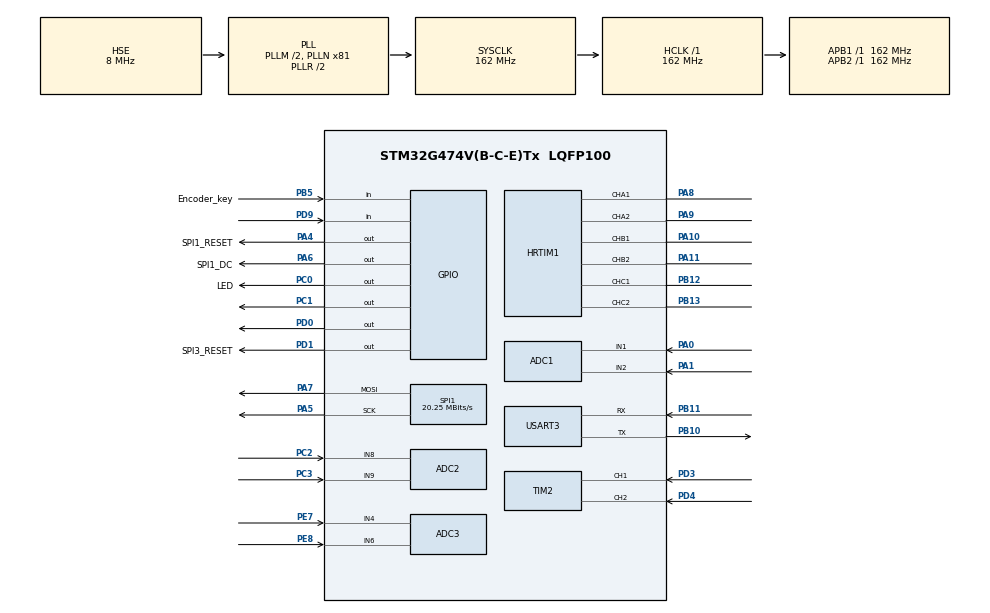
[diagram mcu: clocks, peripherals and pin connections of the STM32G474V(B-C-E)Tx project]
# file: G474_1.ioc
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ADC1.Channel-6\#ChannelRegularConversion=ADC_CHANNEL_1
ADC1.Channel-7\#ChannelRegularConversion=ADC_CHANNEL_2
ADC1.ClockPrescaler=ADC_CLOCK_ASYNC_DIV4
ADC1.ContinuousConvMode=DISABLE
ADC1.DMAAccessModeView=ENABLE
ADC1.DMAContinuousRequests=ENABLE
ADC1.DiscontinuousConvMode=DISABLE
ADC1.EnableAnalogWatchDog1=false
ADC1.EnableInjectedConversion=DISABLE
ADC1.EnableRegularConversion=ENABLE
ADC1.ExternalTrigConv=ADC_EXTERNALTRIG_HRTIM_TRG5
ADC1.ExternalTrigConvEdge=ADC_EXTERNALTRIGCONVEDGE_RISING
ADC1.Mode=ADC_DUALMODE_REGSIMULT
ADC1.NbrOfConversion=2
ADC1.NbrOfConversionFlag=1
ADC1.OffsetNumber-6\#ChannelRegularConversion=ADC_OFFSET_NONE
ADC1.OffsetNumber-7\#ChannelRegularConversion=ADC_OFFSET_NONE
ADC1.Overrun=ADC_OVR_DATA_OVERWRITTEN
ADC1.OversamplingMode=ENABLE
ADC1.OversamplingStopReset=ADC_REGOVERSAMPLING_CONTINUED_MODE
ADC1.Rank-6\#ChannelRegularConversion=1
ADC1.Rank-7\#ChannelRegularConversion=2
ADC1.Ratio=ADC_OVERSAMPLING_RATIO_4
ADC1.RightBitShift=ADC_RIGHTBITSHIFT_2
ADC1.SamplingTime-6\#ChannelRegularConversion=ADC_SAMPLETIME_12CYCLES_5
ADC1.SamplingTime-7\#ChannelRegularConversion=ADC_SAMPLETIME_12CYCLES_5
ADC1.TriggeredMode=ADC_TRIGGEREDMODE_SINGLE_TRIGGER
ADC1.master=1
ADC2.Channel-3\#ChannelRegularConversion=ADC_CHANNEL_8
ADC2.Channel-4\#ChannelRegularConversion=ADC_CHANNEL_9
ADC2.ClockPrescaler=ADC_CLOCK_ASYNC_DIV4
ADC2.DMAAccessModeView=ENABLE
ADC2.Mode=ADC_DUALMODE_REGSIMULT
ADC2.NbrOfConversion=2
ADC2.NbrOfConversionFlag=1
ADC2.OffsetNumber-3\#ChannelRegularConversion=ADC_OFFSET_NONE
ADC2.OffsetNumber-4\#ChannelRegularConversion=ADC_OFFSET_NONE
ADC2.Overrun=ADC_OVR_DATA_OVERWRITTEN
ADC2.OversamplingMode=ENABLE
ADC2.Rank-3\#ChannelRegularConversion=1
ADC2.Rank-4\#ChannelRegularConversion=2
ADC2.Ratio=ADC_OVERSAMPLING_RATIO_4
ADC2.RightBitShift=ADC_RIGHTBITSHIFT_2
ADC2.SamplingTime-3\#ChannelRegularConversion=ADC_SAMPLETIME_12CYCLES_5
ADC2.SamplingTime-4\#ChannelRegularConversion=ADC_SAMPLETIME_12CYCLES_5
ADC3.Channel-0\#ChannelRegularConversion=ADC_CHANNEL_4
ADC3.Channel-1\#ChannelRegularConversion=ADC_CHANNEL_6
ADC3.DMAContinuousRequests=ENABLE
ADC3.ExternalTrigConv=ADC_EXTERNALTRIG_HRTIM_TRG5
ADC3.Mode=ADC_MODE_INDEPENDENT
ADC3.NbrOfConversion=2
ADC3.NbrOfConversionFlag=1
ADC3.OffsetNumber-0\#ChannelRegularConversion=ADC_OFFSET_NONE
ADC3.OffsetNumber-1\#ChannelRegularConversion=ADC_OFFSET_NONE
ADC3.Overrun=ADC_OVR_DATA_OVERWRITTEN
ADC3.OversamplingMode=ENABLE
ADC3.Rank-0\#ChannelRegularConversion=1
ADC3.Rank-1\#ChannelRegularConversion=2
ADC3.Ratio=ADC_OVERSAMPLING_RATIO_4
ADC3.RightBitShift=ADC_RIGHTBITSHIFT_2
ADC3.SamplingTime-0\#ChannelRegularConversion=ADC_SAMPLETIME_12CYCLES_5
ADC3.SamplingTime-1\#ChannelRegularConversion=ADC_SAMPLETIME_12CYCLES_5
ADC3.master=1
Dma.ADC1.1.Direction=DMA_PERIPH_TO_MEMORY
Dma.ADC1.1.EventEnable=DISABLE
Dma.ADC1.1.Instance=DMA1_Channel1
Dma.ADC1.1.MemDataAlignment=DMA_MDATAALIGN_WORD
Dma.ADC1.1.MemInc=DMA_MINC_ENABLE
Dma.ADC1.1.Mode=DMA_CIRCULAR
Dma.ADC1.1.PeriphDataAlignment=DMA_PDATAALIGN_WORD
Dma.ADC1.1.PeriphInc=DMA_PINC_DISABLE
Dma.ADC1.1.Polarity=HAL_DMAMUX_REQ_GEN_RISING
Dma.ADC1.1.Priority=DMA_PRIORITY_MEDIUM
Dma.ADC1.1.RequestNumber=1
Dma.ADC1.1.SignalID=NONE
Dma.ADC1.1.SyncEnable=DISABLE
Dma.ADC1.1.SyncPolarity=HAL_DMAMUX_SYNC_NO_EVENT
Dma.ADC1.1.SyncRequestNumber=1
Dma.ADC1.1.SyncSignalID=NONE
Dma.ADC3.2.Direction=DMA_PERIPH_TO_MEMORY
Dma.ADC3.2.EventEnable=DISABLE
Dma.ADC3.2.Instance=DMA1_Channel2
Dma.ADC3.2.MemDataAlignment=DMA_MDATAALIGN_HALFWORD
Dma.ADC3.2.MemInc=DMA_MINC_ENABLE
Dma.ADC3.2.Mode=DMA_CIRCULAR
Dma.ADC3.2.PeriphDataAlignment=DMA_PDATAALIGN_HALFWORD
Dma.ADC3.2.PeriphInc=DMA_PINC_DISABLE
Dma.ADC3.2.Polarity=HAL_DMAMUX_REQ_GEN_RISING
Dma.ADC3.2.Priority=DMA_PRIORITY_MEDIUM
Dma.ADC3.2.RequestNumber=1
Dma.ADC3.2.SignalID=NONE
Dma.ADC3.2.SyncEnable=DISABLE
Dma.ADC3.2.SyncPolarity=HAL_DMAMUX_SYNC_NO_EVENT
Dma.ADC3.2.SyncRequestNumber=1
Dma.ADC3.2.SyncSignalID=NONE
Dma.Request0=SPI1_TX
Dma.Request1=ADC1
Dma.Request2=ADC3
Dma.Request3=USART3_TX
Dma.Request4=USART3_RX
Dma.SPI1_TX.0.Direction=DMA_MEMORY_TO_PERIPH
Dma.SPI1_TX.0.EventEnable=DISABLE
Dma.SPI1_TX.0.Instance=DMA2_Channel1
Dma.SPI1_TX.0.MemDataAlignment=DMA_MDATAALIGN_BYTE
Dma.SPI1_TX.0.MemInc=DMA_MINC_ENABLE
Dma.SPI1_TX.0.Mode=DMA_NORMAL
Dma.SPI1_TX.0.PeriphDataAlignment=DMA_PDATAALIGN_BYTE
Dma.SPI1_TX.0.PeriphInc=DMA_PINC_DISABLE
Dma.SPI1_TX.0.Polarity=HAL_DMAMUX_REQ_GEN_RISING
Dma.SPI1_TX.0.Priority=DMA_PRIORITY_HIGH
Dma.SPI1_TX.0.RequestNumber=1
Dma.SPI1_TX.0.SignalID=NONE
Dma.SPI1_TX.0.SyncEnable=DISABLE
Dma.SPI1_TX.0.SyncPolarity=HAL_DMAMUX_SYNC_NO_EVENT
Dma.SPI1_TX.0.SyncRequestNumber=1
Dma.SPI1_TX.0.SyncSignalID=NONE
Dma.USART3_RX.4.Direction=DMA_PERIPH_TO_MEMORY
Dma.USART3_RX.4.EventEnable=DISABLE
Dma.USART3_RX.4.Instance=DMA1_Channel4
Dma.USART3_RX.4.MemDataAlignment=DMA_MDATAALIGN_BYTE
Dma.USART3_RX.4.MemInc=DMA_MINC_ENABLE
Dma.USART3_RX.4.Mode=DMA_NORMAL
Dma.USART3_RX.4.PeriphDataAlignment=DMA_PDATAALIGN_BYTE
Dma.USART3_RX.4.PeriphInc=DMA_PINC_DISABLE
Dma.USART3_RX.4.Polarity=HAL_DMAMUX_REQ_GEN_RISING
Dma.USART3_RX.4.Priority=DMA_PRIORITY_MEDIUM
Dma.USART3_RX.4.RequestNumber=1
Dma.USART3_RX.4.SignalID=NONE
Dma.USART3_RX.4.SyncEnable=DISABLE
Dma.USART3_RX.4.SyncPolarity=HAL_DMAMUX_SYNC_NO_EVENT
Dma.USART3_RX.4.SyncRequestNumber=1
Dma.USART3_RX.4.SyncSignalID=NONE
Dma.USART3_TX.3.Direction=DMA_MEMORY_TO_PERIPH
Dma.USART3_TX.3.EventEnable=DISABLE
Dma.USART3_TX.3.Instance=DMA1_Channel3
Dma.USART3_TX.3.MemDataAlignment=DMA_MDATAALIGN_BYTE
Dma.USART3_TX.3.MemInc=DMA_MINC_ENABLE
Dma.USART3_TX.3.Mode=DMA_NORMAL
Dma.USART3_TX.3.PeriphDataAlignment=DMA_PDATAALIGN_BYTE
Dma.USART3_TX.3.PeriphInc=DMA_PINC_DISABLE
Dma.USART3_TX.3.Polarity=HAL_DMAMUX_REQ_GEN_RISING
Dma.USART3_TX.3.Priority=DMA_PRIORITY_MEDIUM
Dma.USART3_TX.3.RequestNumber=1
Dma.USART3_TX.3.SignalID=NONE
Dma.USART3_TX.3.SyncEnable=DISABLE
Dma.USART3_TX.3.SyncPolarity=HAL_DMAMUX_SYNC_NO_EVENT
Dma.USART3_TX.3.SyncRequestNumber=1
Dma.USART3_TX.3.SyncSignalID=NONE
FREERTOS.Tasks01=defaultTask,24,1024,StartDefaultTask,Default,NULL,Dynamic,NULL,NULL
FREERTOS.configCHECK_FOR_STACK_OVERFLOW=2
FREERTOS.configENABLE_FPU=1
FREERTOS.configTOTAL_HEAP_SIZE=49152
FREERTOS.configUSE_TICK_HOOK=1
HRTIM1.ADCTrigger_Id1=__NULL
HRTIM1.ADCTrigger_Id5=HRTIM_ADCTRIGGER_5
HRTIM1.CompareUnit1-MasterTimer=HRTIM_COMPAREUNIT_1
HRTIM1.CompareUnit1-Output_TA1TA2=HRTIM_COMPAREUNIT_1
HRTIM1.CompareUnit1-Output_TB1TB2=HRTIM_COMPAREUNIT_1
HRTIM1.CompareUnit1-Output_TC1TC2=HRTIM_COMPAREUNIT_1
HRTIM1.CompareUnit2-Output_TB1TB2=__NULL
HRTIM1.CompareUnit3-Output_TA1TA2=HRTIM_COMPAREUNIT_3
HRTIM1.CompareUnit3-Output_TB1TB2=HRTIM_COMPAREUNIT_3
HRTIM1.CompareUnit3-Output_TC1TC2=HRTIM_COMPAREUNIT_3
HRTIM1.CompareValue1-MasterTimer=PWM_Period / 2
HRTIM1.CompareValue1-Output_TA1TA2=0
HRTIM1.CompareValue1-Output_TB1TB2=0
HRTIM1.CompareValue1-Output_TC1TC2=0
HRTIM1.CompareValue3-Output_TA1TA2=0
HRTIM1.CompareValue3-Output_TB1TB2=0
HRTIM1.CompareValue3-Output_TC1TC2=0
HRTIM1.DeadTimeInsertion-Output_TA1TA2=HRTIM_TIMDEADTIMEINSERTION_ENABLED
HRTIM1.DeadTimeInsertion-Output_TB1TB2=HRTIM_TIMDEADTIMEINSERTION_ENABLED
HRTIM1.DeadTimeInsertion-Output_TC1TC2=HRTIM_TIMDEADTIMEINSERTION_ENABLED
HRTIM1.Enable=HRTIM_BURSTMODECTL_DISABLED
HRTIM1.Event_EEV1=__NULL
HRTIM1.Event_EEV5=__NULL
HRTIM1.InterruptRequests1_Master=HRTIM_MASTER_IT_MREP
HRTIM1.NumberDMARequests_Master=0
HRTIM1.NumberDMARequests_TA=0
HRTIM1.NumberInterruptRequests_Master-MasterTimer=1
HRTIM1.NumberResetSource1-Output_TA1TA2=1
HRTIM1.NumberResetSource1-Output_TB1TB2=1
HRTIM1.NumberResetSource1-Output_TC1TC2=1
HRTIM1.NumberResetTrigger-Output_TA1TA2=1
HRTIM1.NumberResetTrigger-Output_TB1TB2=1
HRTIM1.NumberResetTrigger-Output_TC1TC2=1
HRTIM1.NumberSetSource1-Output_TA1TA2=1
HRTIM1.NumberSetSource1-Output_TB1TB2=1
HRTIM1.NumberSetSource1-Output_TC1TC2=1
HRTIM1.ORingUpdateSource_ADCTrigger5=HRTIM_ADCTRIGGERUPDATE_MASTER
HRTIM1.Periode_MASTER=PWM_Period
HRTIM1.Periode_TA=PWM_Period
HRTIM1.Periode_TB=PWM_Period
HRTIM1.Periode_TC=PWM_Period
HRTIM1.PreloadEnable-Output_TA1TA2=HRTIM_PRELOAD_ENABLED
HRTIM1.PreloadEnable-Output_TB1TB2=HRTIM_PRELOAD_ENABLED
HRTIM1.PreloadEnable-Output_TC1TC2=HRTIM_PRELOAD_ENABLED
HRTIM1.PrescalerRatio_MASTER=HRTIM_PRESCALERRATIO_MUL8
HRTIM1.PrescalerRatio_TA=HRTIM_PRESCALERRATIO_MUL8
HRTIM1.PrescalerRatio_TB=HRTIM_PRESCALERRATIO_MUL8
HRTIM1.PrescalerRatio_TC=HRTIM_PRESCALERRATIO_MUL8
HRTIM1.RepetitionUpdate-Output_TA1TA2=HRTIM_UPDATEONREPETITION_ENABLED
HRTIM1.RepetitionUpdate-Output_TB1TB2=HRTIM_UPDATEONREPETITION_ENABLED
HRTIM1.RepetitionUpdate-Output_TC1TC2=HRTIM_UPDATEONREPETITION_ENABLED
HRTIM1.ResetOutput1_Source1-Output_TA1TA2=HRTIM_OUTPUTRESET_TIMCMP3
HRTIM1.ResetOutput1_Source1-Output_TB1TB2=HRTIM_OUTPUTRESET_TIMCMP3
HRTIM1.ResetOutput1_Source1-Output_TC1TC2=HRTIM_OUTPUTRESET_TIMCMP3
HRTIM1.ResetTrigger1-Output_TA1TA2=HRTIM_TIMRESETTRIGGER_MASTER_PER
HRTIM1.ResetTrigger1-Output_TB1TB2=HRTIM_TIMRESETTRIGGER_MASTER_PER
HRTIM1.ResetTrigger1-Output_TC1TC2=HRTIM_TIMRESETTRIGGER_MASTER_PER
HRTIM1.ResetUpdate-Output_TA1TA2=HRTIM_TIMUPDATEONRESET_ENABLED
HRTIM1.ResetUpdate-Output_TB1TB2=HRTIM_TIMUPDATEONRESET_ENABLED
HRTIM1.ResetUpdate-Output_TC1TC2=HRTIM_TIMUPDATEONRESET_ENABLED
HRTIM1.SetOutput1_Source1-Output_TA1TA2=HRTIM_OUTPUTSET_TIMCMP1
HRTIM1.SetOutput1_Source1-Output_TB1TB2=HRTIM_OUTPUTSET_TIMCMP1
HRTIM1.SetOutput1_Source1-Output_TC1TC2=HRTIM_OUTPUTSET_TIMCMP1
HRTIM1.Source_ADCTrigger5=HRTIM_ADCTRIGGEREVENT579_MASTER_CMP1
HRTIM1.postscaler5=5
Mcu.Family=STM32G4
Mcu.Name=STM32G474V(B-C-E)Tx
Mcu.Package=LQFP100
Mcu.UserConstants=Handle1,$$_HRTIM1_IP_HANDLE_$$;PWM_Period,36000
NVIC.ADC1_2_IRQn=true\:5\:0\:false\:false\:true\:true\:true\:true\:true
NVIC.DMA1_Channel1_IRQn=true\:5\:0\:true\:false\:true\:true\:false\:true\:true
NVIC.DMA1_Channel2_IRQn=true\:5\:0\:false\:false\:true\:true\:true\:true\:true
NVIC.DMA1_Channel3_IRQn=true\:5\:0\:false\:false\:true\:true\:true\:true\:true
NVIC.DMA1_Channel4_IRQn=true\:5\:0\:false\:false\:true\:true\:true\:true\:true
NVIC.DMA2_Channel1_IRQn=true\:5\:0\:false\:false\:true\:true\:true\:true\:true
NVIC.HRTIM1_Master_IRQn=true\:4\:0\:true\:false\:true\:false\:true\:true\:true
NVIC.PriorityGroup=NVIC_PRIORITYGROUP_4
NVIC.SPI1_IRQn=true\:5\:0\:false\:false\:true\:true\:true\:true\:true
NVIC.TIM1_UP_TIM16_IRQn=true\:15\:0\:false\:false\:true\:false\:false\:true\:true
NVIC.TimeBase=TIM1_UP_TIM16_IRQn
NVIC.TimeBaseIP=TIM1
NVIC.USART3_IRQn=true\:5\:0\:false\:false\:true\:true\:true\:true\:true
PA0.Mode=IN1-Single-Ended
PA0.Signal=ADC1_IN1
PA1.Mode=IN2-Single-Ended
PA1.Signal=ADC1_IN2
PA10.Mode=Output_TB1TB2
PA10.Signal=HRTIM1_CHB1
PA11.Mode=Output_TB1TB2
PA11.Signal=HRTIM1_CHB2
PA13.Mode=Serial_Wire
PA13.Signal=SYS_JTMS-SWDIO
PA14.Mode=Serial_Wire
PA14.Signal=SYS_JTCK-SWCLK
PA4.GPIO_Label=SPI1_RESET
PA4.GPIO_Speed=GPIO_SPEED_FREQ_HIGH
PA4.Signal=GPIO_Output
PA5.GPIO_Speed=GPIO_SPEED_FREQ_HIGH
PA5.Mode=TX_Only_Simplex_Unidirect_Master
PA5.Signal=SPI1_SCK
PA6.GPIO_Label=SPI1_DC
PA6.GPIO_Speed=GPIO_SPEED_FREQ_HIGH
PA6.Signal=GPIO_Output
PA7.GPIO_Speed=GPIO_SPEED_FREQ_HIGH
PA7.Mode=TX_Only_Simplex_Unidirect_Master
PA7.Signal=SPI1_MOSI
PA8.Mode=Output_TA1TA2
PA8.Signal=HRTIM1_CHA1
PA9.Mode=Output_TA1TA2
PA9.Signal=HRTIM1_CHA2
PB10.Mode=Asynchronous
PB10.Signal=USART3_TX
PB11.Mode=Asynchronous
PB11.Signal=USART3_RX
PB12.Mode=Output_TC1TC2
PB12.Signal=HRTIM1_CHC1
PB13.Mode=Output_TC1TC2
PB13.Signal=HRTIM1_CHC2
PB5.GPIO_Label=Encoder_key
PB5.GPIO_PuPd=GPIO_PULLUP
PB5.Signal=GPIO_Input
PC0.GPIO_Label=LED
PC0.Signal=GPIO_Output
PC1.Signal=GPIO_Output
PC2.Mode=IN8-Single-Ended
PC2.Signal=ADC2_IN8
PC3.Mode=IN9-Single-Ended
PC3.Signal=ADC2_IN9
PD0.Signal=GPIO_Output
PD1.GPIO_Label=SPI3_RESET
PD1.Signal=GPIO_Output
PD3.GPIO_PuPd=GPIO_PULLUP
PD3.Signal=S_TIM2_CH1
PD4.GPIO_PuPd=GPIO_PULLUP
PD4.Signal=S_TIM2_CH2
PD9.GPIO_PuPd=GPIO_PULLDOWN
PD9.Signal=GPIO_Input
PE7.Mode=IN4-Single-Ended
PE7.Signal=ADC3_IN4
PE8.Mode=IN6-Single-Ended
PE8.Signal=ADC3_IN6
PF0-OSC_IN.Mode=HSE-External-Oscillator
PF0-OSC_IN.Signal=RCC_OSC_IN
PF1-OSC_OUT.Mode=HSE-External-Oscillator
PF1-OSC_OUT.Signal=RCC_OSC_OUT
ProjectManager.HeapSize=0x200
ProjectManager.StackSize=0x400
ProjectManager.TargetToolchain=CMake
RCC.ADC12Freq_Value=162000000
RCC.ADC345Freq_Value=162000000
RCC.AHBFreq_Value=162000000
RCC.APB1Freq_Value=162000000
RCC.APB1TimFreq_Value=162000000
RCC.APB2Freq_Value=162000000
RCC.APB2TimFreq_Value=162000000
RCC.CK48CLockSelection=RCC_USBCLKSOURCE_HSI48
RCC.CortexFreq_Value=162000000
RCC.EXTERNAL_CLOCK_VALUE=12288000
RCC.EnbaleCSS=true
RCC.HCLKFreq_Value=162000000
RCC.HSE_VALUE=8000000
RCC.HSI48_VALUE=48000000
RCC.HSI_VALUE=16000000
RCC.LSE_VALUE=32768
RCC.PLLM=RCC_PLLM_DIV2
RCC.PLLN=81
RCC.PLLSourceVirtual=RCC_PLLSOURCE_HSE
RCC.SYSCLKFreq_VALUE=162000000
RCC.SYSCLKSource=RCC_SYSCLKSOURCE_PLLCLK
RCC.USBFreq_Value=48000000
RCC.VCOOutputFreq_Value=324000000
SH.S_TIM2_CH1.0=TIM2_CH1,Encoder_Interface
SH.S_TIM2_CH2.0=TIM2_CH2,Encoder_Interface
SPI1.BaudRatePrescaler=SPI_BAUDRATEPRESCALER_8
SPI1.CalculateBaudRate=20.25 MBits/s
SPI1.DataSize=SPI_DATASIZE_8BIT
SPI1.Direction=SPI_DIRECTION_2LINES
SPI1.Mode=SPI_MODE_MASTER
SPI1.NSSPMode=SPI_NSS_PULSE_DISABLE
SPI1.VirtualType=VM_MASTER
STMicroelectronics.X-CUBE-ALGOBUILD.1.4.0.LibraryCcDSPOoLibraryJjDSPOoLibrary=true
TIM2.ClockDivision=TIM_CLOCKDIVISION_DIV1
TIM2.Dithering=Disable
TIM2.EncoderMode=TIM_ENCODERMODE_TI12
TIM2.IC1Filter=0
TIM2.IC1Prescaler=TIM_ICPSC_DIV1
TIM2.IC2Filter=0
TIM2.IC2Prescaler=TIM_ICPSC_DIV1
USART3.VirtualMode-Asynchronous=VM_ASYNC
VP_FREERTOS_VS_CMSIS_V2.Mode=CMSIS_V2
VP_HRTIM1_VS_hrtimMasterTimerNoOutput.Mode=MasterTimer
VP_STMicroelectronics.X-CUBE-ALGOBUILD_VS_DSPOoLibraryJjLibrary_1.4.0_1.4.0.Mode=DSPOoLibraryJjLibrary
VP_SYS_VS_DBSignals.Mode=DisableDeadBatterySignals
VP_SYS_VS_tim1.Mode=TIM1
VP_SYS_V_VREFBUF.Mode=ExternalMode
board=custom

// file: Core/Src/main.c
/* USER CODE BEGIN Header */
/**
  ******************************************************************************
  * @file           : main.c
  * @brief          : Main program body
  ******************************************************************************
  * @attention
  *
  * Copyright (c) 2025 STMicroelectronics.
  * All rights reserved.
  *
  * This software is licensed under terms that can be found in the LICENSE file
  * in the root directory of this software component.
  * If no LICENSE file comes with this software, it is provided AS-IS.
  *
  ******************************************************************************
  */
/* USER CODE END Header */
#include "main.h"
#include "cmsis_os.h"
#include "adc.h"
#include "dma.h"
#include "hrtim.h"
#include "spi.h"
#include "tim.h"
#include "usart.h"
#include "gpio.h"

void SystemClock_Config(void);
void MX_FREERTOS_Init(void);

int main(void)
{

  /* MCU Configuration--------------------------------------------------------*/

  /* Reset of all peripherals, Initializes the Flash interface and the Systick. */
  HAL_Init();

  /* Configure the system clock */
  SystemClock_Config();

  /* Initialize all configured peripherals */
  MX_GPIO_Init();
  MX_DMA_Init();
  MX_ADC1_Init();
  MX_HRTIM1_Init();
  MX_SPI1_Init();
  MX_ADC2_Init();
  MX_ADC3_Init();
  MX_USART3_UART_Init();
  MX_TIM2_Init();

  /* Init scheduler */
  osKernelInitialize();  /* Call init function for freertos objects (in cmsis_os2.c) */
  MX_FREERTOS_Init();

  /* Start scheduler */
  osKernelStart();

  /* We should never get here as control is now taken by the scheduler */

  /* Infinite loop */
  while(1)
  {

  }
}

void SystemClock_Config(void)
{
  RCC_OscInitTypeDef RCC_OscInitStruct = {0};
  RCC_ClkInitTypeDef RCC_ClkInitStruct = {0};

  /** Configure the main internal regulator output voltage
  */
  HAL_PWREx_ControlVoltageScaling(PWR_REGULATOR_VOLTAGE_SCALE1_BOOST);

  /** Initializes the RCC Oscillators according to the specified parameters
  * in the RCC_OscInitTypeDef structure.
  */
  RCC_OscInitStruct.OscillatorType = RCC_OSCILLATORTYPE_HSE;
  RCC_OscInitStruct.HSEState = RCC_HSE_ON;
  RCC_OscInitStruct.PLL.PLLState = RCC_PLL_ON;
  RCC_OscInitStruct.PLL.PLLSource = RCC_PLLSOURCE_HSE;
  RCC_OscInitStruct.PLL.PLLM = RCC_PLLM_DIV2;
  RCC_OscInitStruct.PLL.PLLN = 81;
  RCC_OscInitStruct.PLL.PLLP = RCC_PLLP_DIV2;
  RCC_OscInitStruct.PLL.PLLQ = RCC_PLLQ_DIV2;
  RCC_OscInitStruct.PLL.PLLR = RCC_PLLR_DIV2;
  if (HAL_RCC_OscConfig(&RCC_OscInitStruct) != HAL_OK)
  {
    Error_Handler();
  }

  /** Initializes the CPU, AHB and APB buses clocks
  */
  RCC_ClkInitStruct.ClockType = RCC_CLOCKTYPE_HCLK|RCC_CLOCKTYPE_SYSCLK
                              |RCC_CLOCKTYPE_PCLK1|RCC_CLOCKTYPE_PCLK2;
  RCC_ClkInitStruct.SYSCLKSource = RCC_SYSCLKSOURCE_PLLCLK;
  RCC_ClkInitStruct.AHBCLKDivider = RCC_SYSCLK_DIV1;
  RCC_ClkInitStruct.APB1CLKDivider = RCC_HCLK_DIV1;
  RCC_ClkInitStruct.APB2CLKDivider = RCC_HCLK_DIV1;

  if (HAL_RCC_ClockConfig(&RCC_ClkInitStruct, FLASH_LATENCY_4) != HAL_OK)
  {
    Error_Handler();
  }

  /** Enables the Clock Security System
  */
  HAL_RCC_EnableCSS();
}

void HAL_TIM_PeriodElapsedCallback(TIM_HandleTypeDef *htim)
{
  if (htim->Instance == TIM1)
  {
    HAL_IncTick();
  }
}

void Error_Handler(void)
{
  /* USER CODE BEGIN Error_Handler_Debug */
  /* User can add his own implementation to report the HAL error return state */
  __disable_irq();
  while(1)
  {}
  /* USER CODE END Error_Handler_Debug */
}

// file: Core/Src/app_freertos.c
/* USER CODE BEGIN Header */
/**
  ******************************************************************************
  * File Name          : app_freertos.c
  * Description        : Code for freertos applications
  ******************************************************************************
  * @attention
  *
  * Copyright (c) 2025 STMicroelectronics.
  * All rights reserved.
  *
  * This software is licensed under terms that can be found in the LICENSE file
  * in the root directory of this software component.
  * If no LICENSE file comes with this software, it is provided AS-IS.
  *
  ******************************************************************************
  */
/* USER CODE END Header */

#include "FreeRTOS.h"
#include "task.h"
#include "main.h"
#include "cmsis_os.h"

/* USER CODE BEGIN Includes */
#include <stdio.h>

#include "lvgl.h"
/* USER CODE END Includes */

/* Definitions for defaultTask */
osThreadId_t defaultTaskHandle;
const osThreadAttr_t defaultTask_attributes = {
  .name = "defaultTask",
  .priority = (osPriority_t) osPriorityNormal,
  .stack_size = 1024 * 4
};

void StartDefaultTask(void *argument);

void MX_FREERTOS_Init(void); /* (MISRA C 2004 rule 8.1) */

/* Hook prototypes */
void configureTimerForRunTimeStats(void);
unsigned long getRunTimeCounterValue(void);
void vApplicationTickHook(void);
void vApplicationStackOverflowHook(xTaskHandle xTask, signed char *pcTaskName);

/* USER CODE BEGIN 1 */
/* Functions needed when configGENERATE_RUN_TIME_STATS is on */
__weak void configureTimerForRunTimeStats(void)
{}

__weak unsigned long getRunTimeCounterValue(void)
{
  return 0;
}

/* USER CODE END 1 */

/* USER CODE BEGIN 3 */
void vApplicationTickHook(void)
{
  /* This function will be called by each tick interrupt if
  configUSE_TICK_HOOK is set to 1 in FreeRTOSConfig.h. User code can be
  added here, but the tick hook is called from an interrupt context, so
  code must not attempt to block, and only the interrupt safe FreeRTOS API
  functions can be used (those that end in FromISR()). */
  lv_tick_inc(1);
}

/* USER CODE END 3 */

/* USER CODE BEGIN 4 */
void vApplicationStackOverflowHook(xTaskHandle xTask, signed char *pcTaskName)
{
  (void)xTask;
  printf("Stack overflow in task: %s\n", (char *)pcTaskName);
  taskDISABLE_INTERRUPTS();
  for(;;);
}

/* USER CODE END 4 */

void MX_FREERTOS_Init(void) {

  /* Create the thread(s) */
  /* creation of defaultTask */
  defaultTaskHandle = osThreadNew(StartDefaultTask, NULL, &defaultTask_attributes);

}

void StartDefaultTask(void *argument)
{
  /* USER CODE BEGIN StartDefaultTask */
  /* Infinite loop */
  app_main();
  // while(1)
  // {
  //   vTaskDelay(100);
  // }
  vTaskDelete(NULL);
  /* USER CODE END StartDefaultTask */
}
